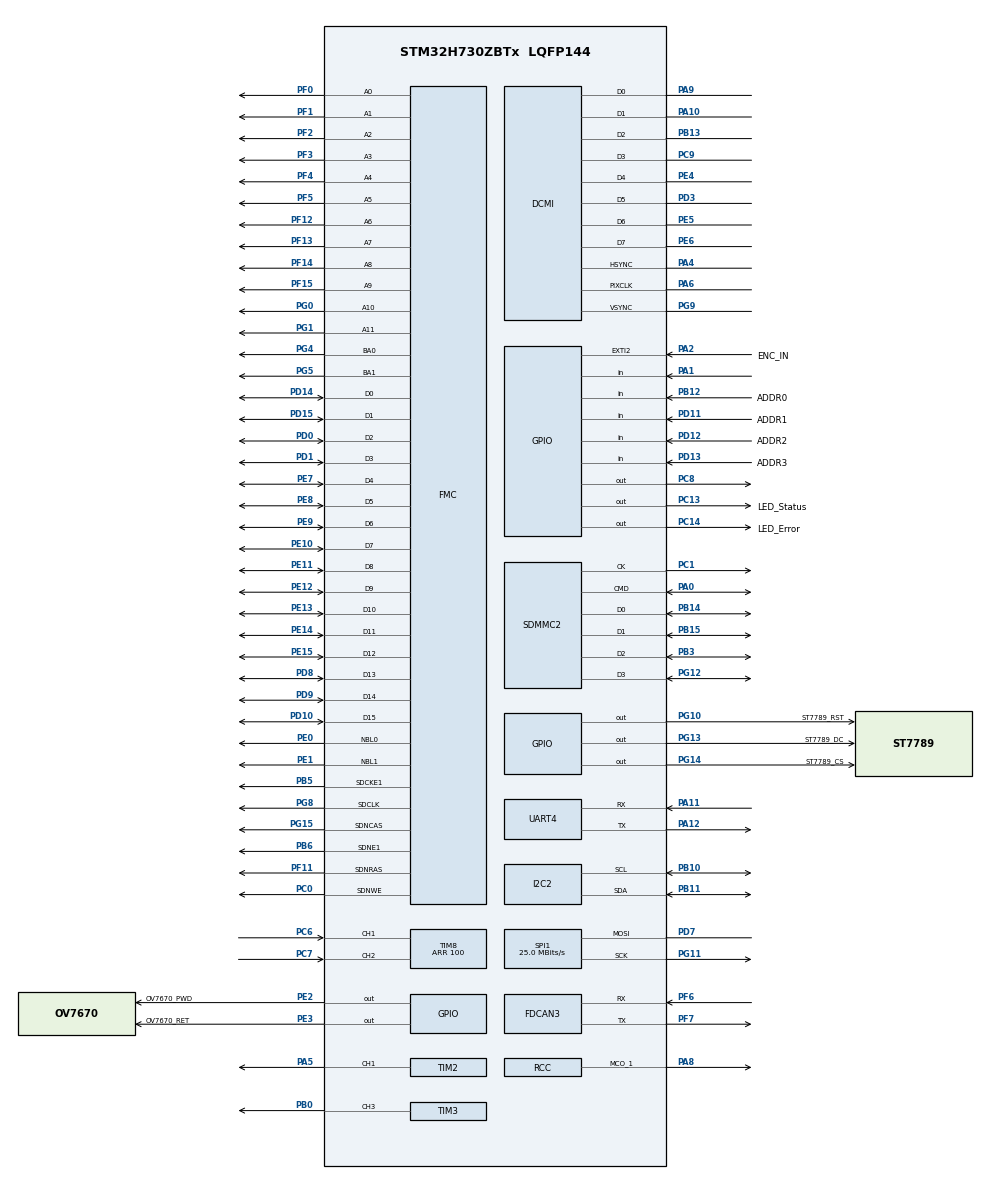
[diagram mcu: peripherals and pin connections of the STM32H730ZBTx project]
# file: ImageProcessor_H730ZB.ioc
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CORTEX_M7.CPU_DCache=Enabled
CORTEX_M7.CPU_ICache=Enabled
DCMI.JPEGMode=DCMI_JPEG_DISABLE
DCMI.PCKPolarity=DCMI_PCKPOLARITY_RISING
DCMI.VSPolarity=DCMI_VSPOLARITY_HIGH
Dma.DCMI_PSSI.0.Direction=DMA_PERIPH_TO_MEMORY
Dma.DCMI_PSSI.0.EventEnable=DISABLE
Dma.DCMI_PSSI.0.FIFOMode=DMA_FIFOMODE_ENABLE
Dma.DCMI_PSSI.0.FIFOThreshold=DMA_FIFO_THRESHOLD_FULL
Dma.DCMI_PSSI.0.Instance=DMA2_Stream0
Dma.DCMI_PSSI.0.MemBurst=DMA_MBURST_SINGLE
Dma.DCMI_PSSI.0.MemDataAlignment=DMA_MDATAALIGN_WORD
Dma.DCMI_PSSI.0.MemInc=DMA_MINC_ENABLE
Dma.DCMI_PSSI.0.Mode=DMA_NORMAL
Dma.DCMI_PSSI.0.PeriphBurst=DMA_PBURST_SINGLE
Dma.DCMI_PSSI.0.PeriphDataAlignment=DMA_PDATAALIGN_WORD
Dma.DCMI_PSSI.0.PeriphInc=DMA_PINC_DISABLE
Dma.DCMI_PSSI.0.Polarity=HAL_DMAMUX_REQ_GEN_RISING
Dma.DCMI_PSSI.0.Priority=DMA_PRIORITY_VERY_HIGH
Dma.DCMI_PSSI.0.RequestNumber=1
Dma.DCMI_PSSI.0.SignalID=NONE
Dma.DCMI_PSSI.0.SyncEnable=ENABLE
Dma.DCMI_PSSI.0.SyncPolarity=HAL_DMAMUX_SYNC_RISING
Dma.DCMI_PSSI.0.SyncRequestNumber=1
Dma.DCMI_PSSI.0.SyncSignalID=NONE
Dma.Request0=DCMI_PSSI
Dma.Request1=TIM3_CH3
Dma.TIM3_CH3.1.Direction=DMA_MEMORY_TO_PERIPH
Dma.TIM3_CH3.1.EventEnable=DISABLE
Dma.TIM3_CH3.1.FIFOMode=DMA_FIFOMODE_DISABLE
Dma.TIM3_CH3.1.Instance=DMA1_Stream0
Dma.TIM3_CH3.1.MemDataAlignment=DMA_MDATAALIGN_HALFWORD
Dma.TIM3_CH3.1.MemInc=DMA_MINC_ENABLE
Dma.TIM3_CH3.1.Mode=DMA_NORMAL
Dma.TIM3_CH3.1.PeriphDataAlignment=DMA_PDATAALIGN_HALFWORD
Dma.TIM3_CH3.1.PeriphInc=DMA_PINC_DISABLE
Dma.TIM3_CH3.1.Polarity=HAL_DMAMUX_REQ_GEN_RISING
Dma.TIM3_CH3.1.Priority=DMA_PRIORITY_LOW
Dma.TIM3_CH3.1.RequestNumber=1
Dma.TIM3_CH3.1.SignalID=NONE
Dma.TIM3_CH3.1.SyncEnable=ENABLE
Dma.TIM3_CH3.1.SyncPolarity=HAL_DMAMUX_SYNC_RISING
Dma.TIM3_CH3.1.SyncRequestNumber=1
Dma.TIM3_CH3.1.SyncSignalID=NONE
FATFS.BSP.number=1
FATFS0.BSP.STBoard=false
FATFS0.BSP.api=Unknown
FATFS0.BSP.i2caddr=0
FATFS0.BSP.instance=PA1
FATFS0.BSP.ip=GPIO
FATFS0.BSP.mode=Input
FATFS0.BSP.name=Detect_SDIO
FATFS0.BSP.solution=PA1
FDCAN3.AutoRetransmission=ENABLE
FDCAN3.DataPrescaler=1
FDCAN3.DataSyncJumpWidth=8
FDCAN3.DataTimeSeg1=16
FDCAN3.DataTimeSeg2=16
FDCAN3.ExtFiltersNbr=0
FDCAN3.NominalPrescaler=2
FDCAN3.NominalSyncJumpWidth=8
FDCAN3.NominalTimeSeg1=37
FDCAN3.NominalTimeSeg2=10
FDCAN3.ProtocolException=ENABLE
FDCAN3.RxBuffersNbr=0
FDCAN3.RxFifo0ElmtsNbr=8
FDCAN3.RxFifo1ElmtsNbr=0
FDCAN3.StdFiltersNbr=1
FDCAN3.TransmitPause=DISABLE
FDCAN3.TxBuffersNbr=0
FDCAN3.TxEventsNbr=0
FDCAN3.TxFifoQueueElmtsNbr=8
FMC.BankMapConfig=FMC_SWAPBMAP_DISABLE
FMC.CASLatency1=FMC_SDRAM_CAS_LATENCY_3
FMC.ExitSelfRefreshDelay1=15
FMC.LoadToActiveDelay1=3
FMC.RCDDelay1=4
FMC.RPDelay1=4
FMC.RPDelay2=4
FMC.ReadBurst1=FMC_SDRAM_RBURST_DISABLE
FMC.ReadPipeDelay1=FMC_SDRAM_RPIPE_DELAY_2
FMC.ReadPipeDelay2=FMC_SDRAM_RPIPE_DELAY_2
FMC.RowCycleDelay1=12
FMC.RowCycleDelay2=12
FMC.SDClockPeriod1=FMC_SDRAM_CLOCK_PERIOD_3
FMC.SDClockPeriod2=FMC_SDRAM_CLOCK_PERIOD_3
FMC.SelfRefreshTime1=9
FMC.WriteRecoveryTime1=6
I2C2.Timing=0x10C0ECFF
Mcu.Family=STM32H7
Mcu.Name=STM32H730ZBTx
Mcu.Package=LQFP144
NVIC.DCMI_PSSI_IRQn=true\:0\:0\:false\:false\:true\:true\:true
NVIC.DMA1_Stream0_IRQn=true\:0\:0\:false\:false\:true\:false\:true
NVIC.DMA2_Stream0_IRQn=true\:0\:0\:false\:false\:true\:false\:true
NVIC.DMAMUX1_OVR_IRQn=true\:0\:0\:false\:false\:true\:false\:true
NVIC.EXTI2_IRQn=true\:0\:0\:false\:false\:true\:true\:true
NVIC.FDCAN3_IT0_IRQn=true\:0\:0\:false\:false\:true\:true\:true
NVIC.FDCAN3_IT1_IRQn=true\:0\:0\:false\:false\:true\:true\:true
NVIC.PriorityGroup=NVIC_PRIORITYGROUP_4
NVIC.SPI1_IRQn=true\:0\:0\:false\:false\:true\:true\:true
NVIC.TIM3_IRQn=true\:0\:0\:false\:false\:true\:true\:true
NVIC.TIM8_CC_IRQn=true\:0\:0\:false\:false\:true\:true\:true
PA0.Mode=SD_4_bits_Wide_bus
PA0.Signal=SDMMC2_CMD
PA1.Signal=GPIO_Input
PA10.Mode=Slave_8_bits_External_Synchro
PA10.Signal=DCMI_D1
PA11.Mode=Asynchronous
PA11.Signal=UART4_RX
PA12.Mode=Asynchronous
PA12.Signal=UART4_TX
PA13(JTMS/SWDIO).Mode=Serial_Wire
PA13(JTMS/SWDIO).Signal=DEBUG_JTMS-SWDIO
PA14(JTCK/SWCLK).Mode=Serial_Wire
PA14(JTCK/SWCLK).Signal=DEBUG_JTCK-SWCLK
PA2.GPIO_Label=ENC_IN
PA2.GPIO_ModeDefaultEXTI=GPIO_MODE_IT_FALLING
PA2.Signal=GPXTI2
PA4.Mode=Slave_8_bits_External_Synchro
PA4.Signal=DCMI_HSYNC
PA5.Signal=S_TIM2_CH1
PA6.Mode=Slave_8_bits_External_Synchro
PA6.Signal=DCMI_PIXCLK
PA8.GPIO_Speed=GPIO_SPEED_FREQ_LOW
PA8.Mode=Clock-out-1
PA8.Signal=RCC_MCO_1
PA9.Mode=Slave_8_bits_External_Synchro
PA9.Signal=DCMI_D0
PB0.Signal=S_TIM3_CH3
PB10.Mode=I2C
PB10.Signal=I2C2_SCL
PB11.Mode=I2C
PB11.Signal=I2C2_SDA
PB12.GPIO_Label=ADDR0
PB12.Signal=GPIO_Input
PB13.Mode=Slave_8_bits_External_Synchro
PB13.Signal=DCMI_D2
PB14.Mode=SD_4_bits_Wide_bus
PB14.Signal=SDMMC2_D0
PB15.Mode=SD_4_bits_Wide_bus
PB15.Signal=SDMMC2_D1
PB3(JTDO/TRACESWO).Mode=SD_4_bits_Wide_bus
PB3(JTDO/TRACESWO).Signal=SDMMC2_D2
PB5.Mode=SdramChipSelect2_1
PB5.Signal=FMC_SDCKE1
PB6.Mode=SdramChipSelect2_1
PB6.Signal=FMC_SDNE1
PC0.Signal=FMC_SDNWE
PC1.Mode=SD_4_bits_Wide_bus
PC1.Signal=SDMMC2_CK
PC13.GPIO_Label=LED_Status
PC13.Signal=GPIO_Output
PC14-OSC32_IN.GPIO_Label=LED_Error
PC14-OSC32_IN.Signal=GPIO_Output
PC6.Signal=S_TIM8_CH1
PC7.Signal=S_TIM8_CH2
PC8.Signal=GPIO_Output
PC9.Mode=Slave_8_bits_External_Synchro
PC9.Signal=DCMI_D3
PD0.Signal=FMC_D2_DA2
PD1.Signal=FMC_D3_DA3
PD10.Signal=FMC_D15_DA15
PD11.GPIO_Label=ADDR1
PD11.Signal=GPIO_Input
PD12.GPIO_Label=ADDR2
PD12.Signal=GPIO_Input
PD13.GPIO_Label=ADDR3
PD13.Signal=GPIO_Input
PD14.Signal=FMC_D0_DA0
PD15.Signal=FMC_D1_DA1
PD3.Mode=Slave_8_bits_External_Synchro
PD3.Signal=DCMI_D5
PD7.Mode=Simplex_Bidirectional_Master
PD7.Signal=SPI1_MOSI
PD8.Signal=FMC_D13_DA13
PD9.Signal=FMC_D14_DA14
PE0.Signal=FMC_NBL0
PE1.Signal=FMC_NBL1
PE10.Signal=FMC_D7_DA7
PE11.Signal=FMC_D8_DA8
PE12.Signal=FMC_D9_DA9
PE13.Signal=FMC_D10_DA10
PE14.Signal=FMC_D11_DA11
PE15.Signal=FMC_D12_DA12
PE2.GPIO_Label=OV7670_PWD
PE2.Signal=GPIO_Output
PE3.GPIO_Label=OV7670_RET
PE3.Signal=GPIO_Output
PE4.Mode=Slave_8_bits_External_Synchro
PE4.Signal=DCMI_D4
PE5.Mode=Slave_8_bits_External_Synchro
PE5.Signal=DCMI_D6
PE6.Mode=Slave_8_bits_External_Synchro
PE6.Signal=DCMI_D7
PE7.Signal=FMC_D4_DA4
PE8.Signal=FMC_D5_DA5
PE9.Signal=FMC_D6_DA6
PF0.Signal=FMC_A0
PF1.Signal=FMC_A1
PF11.Signal=FMC_SDNRAS
PF12.Signal=FMC_A6
PF13.Signal=FMC_A7
PF14.Signal=FMC_A8
PF15.Signal=FMC_A9
PF2.Signal=FMC_A2
PF3.Signal=FMC_A3
PF4.Signal=FMC_A4
PF5.Signal=FMC_A5
PF6.Mode=FDCAN_Activate
PF6.Signal=FDCAN3_RX
PF7.Mode=FDCAN_Activate
PF7.Signal=FDCAN3_TX
PG0.Signal=FMC_A10
PG1.Signal=FMC_A11
PG10.GPIO_Label=ST7789_RST
PG10.Signal=GPIO_Output
PG11.Mode=Simplex_Bidirectional_Master
PG11.Signal=SPI1_SCK
PG12.Mode=SD_4_bits_Wide_bus
PG12.Signal=SDMMC2_D3
PG13.GPIO_Label=ST7789_DC
PG13.Signal=GPIO_Output
PG14.GPIO_Label=ST7789_CS
PG14.Signal=GPIO_Output
PG15.Signal=FMC_SDNCAS
PG4.Signal=FMC_A14_BA0
PG5.Signal=FMC_A15_BA1
PG8.Signal=FMC_SDCLK
PG9.Mode=Slave_8_bits_External_Synchro
PG9.Signal=DCMI_VSYNC
PH0-OSC_IN.Mode=HSE-External-Oscillator
PH0-OSC_IN.Signal=RCC_OSC_IN
PH1-OSC_OUT.Mode=HSE-External-Oscillator
PH1-OSC_OUT.Signal=RCC_OSC_OUT
ProjectManager.HeapSize=0x200
ProjectManager.StackSize=0x400
ProjectManager.TargetToolchain=STM32CubeIDE
RCC.ADCFreq_Value=96750000
RCC.APB1Freq_Value=100000000
RCC.APB2Freq_Value=100000000
RCC.APB3Freq_Value=100000000
RCC.APB4Freq_Value=100000000
RCC.CortexFreq_Value=400000000
RCC.D1PPRE=RCC_APB3_DIV2
RCC.D2PPRE1=RCC_APB1_DIV2
RCC.D2PPRE2=RCC_APB2_DIV2
RCC.D3PPRE=RCC_APB4_DIV2
RCC.DIVM1=3
RCC.DIVN1=25
RCC.DIVP1=1
RCC.FDCANCLockSelection=RCC_FDCANCLKSOURCE_HSE
RCC.HCLKFreq_Value=200000000
RCC.HPRE=RCC_HCLK_DIV2
RCC.HSE_VALUE=48000000
RCC.PLL2_VCI_Range-AdvancedSettings=RCC_PLL2VCIRANGE_0
RCC.PLL2_VCO_SEL-AdvancedSettings=RCC_PLL2VCOMEDIUM
RCC.PLL3_VCO_SEL-AdvancedSettings=RCC_PLL3VCOWIDE
RCC.PLLFRACN=0
RCC.PLLSourceVirtual=RCC_PLLSOURCE_HSE
RCC.RCC_MCODiv1=RCC_MCODIV_8
RCC.SYSCLKFreq_VALUE=400000000
RCC.SYSCLKSource=RCC_SYSCLKSOURCE_PLLCLK
RCC.USBFreq_Value=200000000
SH.FMC_A0.0=FMC_A0,12b-sda1
SH.FMC_A1.0=FMC_A1,12b-sda1
SH.FMC_A10.0=FMC_A10,12b-sda1
SH.FMC_A11.0=FMC_A11,12b-sda1
SH.FMC_A14_BA0.0=FMC_BA0,FourSdramBanks1
SH.FMC_A15_BA1.0=FMC_BA1,FourSdramBanks1
SH.FMC_A2.0=FMC_A2,12b-sda1
SH.FMC_A3.0=FMC_A3,12b-sda1
SH.FMC_A4.0=FMC_A4,12b-sda1
SH.FMC_A5.0=FMC_A5,12b-sda1
SH.FMC_A6.0=FMC_A6,12b-sda1
SH.FMC_A7.0=FMC_A7,12b-sda1
SH.FMC_A8.0=FMC_A8,12b-sda1
SH.FMC_A9.0=FMC_A9,12b-sda1
SH.FMC_D0_DA0.0=FMC_D0,sd-16b-d1
SH.FMC_D10_DA10.0=FMC_D10,sd-16b-d1
SH.FMC_D11_DA11.0=FMC_D11,sd-16b-d1
SH.FMC_D12_DA12.0=FMC_D12,sd-16b-d1
SH.FMC_D13_DA13.0=FMC_D13,sd-16b-d1
SH.FMC_D14_DA14.0=FMC_D14,sd-16b-d1
SH.FMC_D15_DA15.0=FMC_D15,sd-16b-d1
SH.FMC_D1_DA1.0=FMC_D1,sd-16b-d1
SH.FMC_D2_DA2.0=FMC_D2,sd-16b-d1
SH.FMC_D3_DA3.0=FMC_D3,sd-16b-d1
SH.FMC_D4_DA4.0=FMC_D4,sd-16b-d1
SH.FMC_D5_DA5.0=FMC_D5,sd-16b-d1
SH.FMC_D6_DA6.0=FMC_D6,sd-16b-d1
SH.FMC_D7_DA7.0=FMC_D7,sd-16b-d1
SH.FMC_D8_DA8.0=FMC_D8,sd-16b-d1
SH.FMC_D9_DA9.0=FMC_D9,sd-16b-d1
SH.FMC_NBL0.0=FMC_NBL0,Sd2ByteEnable1
SH.FMC_NBL1.0=FMC_NBL1,Sd2ByteEnable1
SH.FMC_SDCLK.0=FMC_SDCLK,12b-sda1
SH.FMC_SDNCAS.0=FMC_SDNCAS,12b-sda1
SH.FMC_SDNRAS.0=FMC_SDNRAS,12b-sda1
SH.FMC_SDNWE.0=FMC_SDNWE,12b-sda1
SH.S_TIM2_CH1.0=TIM2_CH1,PWM Generation1 CH1
SH.S_TIM3_CH3.0=TIM3_CH3,PWM Generation3 CH3
SH.S_TIM8_CH1.0=TIM8_CH1,Encoder_Interface
SH.S_TIM8_CH2.0=TIM8_CH2,Encoder_Interface
SPI1.BaudRatePrescaler=SPI_BAUDRATEPRESCALER_8
SPI1.CLKPolarity=SPI_POLARITY_HIGH
SPI1.CalculateBaudRate=25.0 MBits/s
SPI1.DataSize=SPI_DATASIZE_8BIT
SPI1.Direction=SPI_DIRECTION_1LINE
SPI1.Mode=SPI_MODE_MASTER
SPI1.NSSPMode=SPI_NSS_PULSE_DISABLE
SPI1.VirtualType=VM_MASTER
TIM2.Channel-PWM\ Generation1\ CH1=TIM_CHANNEL_1
TIM2.Period=100
TIM2.Prescaler=2000
TIM2.Pulse-PWM\ Generation1\ CH1=50
TIM3.AutoReloadPreload=TIM_AUTORELOAD_PRELOAD_DISABLE
TIM3.Channel-PWM\ Generation3\ CH3=TIM_CHANNEL_3
TIM3.Period=228
TIM3.Prescaler=0
TIM3.Pulse-PWM\ Generation3\ CH3=0
TIM8.AutoReloadPreload=TIM_AUTORELOAD_PRELOAD_ENABLE
TIM8.EncoderMode=TIM_ENCODERMODE_TI12
TIM8.IC1Filter=10
TIM8.IC1Polarity=TIM_ICPOLARITY_FALLING
TIM8.IC2Filter=10
TIM8.Period=100
VP_FATFS_VS_SDIO.Mode=SDIO
VP_TIM2_VS_ClockSourceINT.Mode=Internal
VP_TIM3_VS_ClockSourceINT.Mode=Internal
board=custom

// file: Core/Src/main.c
/* USER CODE BEGIN Header */
/**
  ******************************************************************************
  * @file           : main.c
  * @brief          : Main program body
  ******************************************************************************
  * @attention
  *
  * <h2><center>&copy; Copyright (c) 2020 STMicroelectronics.
  * All rights reserved.</center></h2>
  *
  * This software component is licensed by ST under BSD 3-Clause license,
  * the "License"; You may not use this file except in compliance with the
  * License. You may obtain a copy of the License at:
  *                        opensource.org/licenses/BSD-3-Clause
  *
  ******************************************************************************
  */
/* USER CODE END Header */
#include "main.h"
#include "fatfs.h"

/* USER CODE BEGIN Includes */

#include "ws2812.h"
#include "ov7670.h"
#include "st7789.h"
#include "menu.h"
#include "globals.h"

/* USER CODE END Includes */

/* USER CODE BEGIN PD */

#define BEST_LIGHTNING 55
/* USER CODE END PD */

DCMI_HandleTypeDef hdcmi;
DMA_HandleTypeDef hdma_dcmi_pssi;

FDCAN_HandleTypeDef hfdcan3;

I2C_HandleTypeDef hi2c2;

SD_HandleTypeDef hsd2;

SPI_HandleTypeDef hspi1;

TIM_HandleTypeDef htim2;
TIM_HandleTypeDef htim3;
TIM_HandleTypeDef htim8;
DMA_HandleTypeDef hdma_tim3_ch3;

UART_HandleTypeDef huart4;

SDRAM_HandleTypeDef hsdram1;

/* USER CODE BEGIN PV */
FMC_SDRAM_CommandTypeDef command;

uint16_t framebuffer[OV7670_QVGA_HEIGHT][OV7670_QVGA_WIDTH ];
//WRITE_READ_ADDR
uint16_t *sdramptr = (__IO uint16_t*) (SDRAM_BANK_ADDR );

unsigned char img[MAXYDIM][MAXXDIM];

uint8_t btn_enc = 0;
uint8_t pic_captured = 0;
uint8_t pic_written = 1;
uint8_t led_val;
uint8_t led_val_changed = 0;

//uint32_t cursorLine = 0;
//uint8_t cursorChanged = 0;

/* USER CODE END PV */

void SystemClock_Config(void);
static void MX_GPIO_Init(void);
static void MX_DMA_Init(void);
static void MX_FMC_Init(void);
static void MX_DCMI_Init(void);
static void MX_I2C2_Init(void);
static void MX_SPI1_Init(void);
static void MX_TIM8_Init(void);
static void MX_SDMMC2_SD_Init(void);
static void MX_TIM2_Init(void);
static void MX_UART4_Init(void);
static void MX_TIM3_Init(void);
static void MX_FDCAN3_Init(void);
/* USER CODE BEGIN PFP */
static void SDRAM_Initialization_Sequence(SDRAM_HandleTypeDef *hsdram, FMC_SDRAM_CommandTypeDef *Command);

/* USER CODE END PFP */

/* USER CODE BEGIN 0 */

// Buffers for CAN transmit and can receive
__IO uint8_t ubKeyNumber = 0x0;
FDCAN_RxHeaderTypeDef RxHeader;
uint8_t RxData[8];
FDCAN_TxHeaderTypeDef TxHeader;
uint8_t TxData[8];

/* Read/Write Buffers for RAM test*/
uint32_t aTxBuffer[BUFFER_SIZE];
uint32_t aRxBuffer[BUFFER_SIZE];

/* Status variables */
__IO uint32_t uwWriteReadStatus = 0;
/* Counter index */
uint32_t uwIndex = 0;

static void Fill_Buffer(uint32_t *pBuffer, uint32_t uwBufferLenght, uint32_t uwOffset)
{
  uint32_t tmpIndex = 0;

  /* Put in global buffer different values */
  for (tmpIndex = 0; tmpIndex < uwBufferLenght; tmpIndex++ )
  {
    pBuffer[tmpIndex] = tmpIndex + uwOffset;
  }
}

void SD_RAM_TEST() {
	  /*##-2- SDRAM memory read/write access #####################################*/

	  /* Write data to the SDRAM memory */
	  for(int i = 0; i < 50; i++){
		  /* Fill the buffer to write */
		  Fill_Buffer(aTxBuffer, BUFFER_SIZE, 0xA244250F);

		    /* Fill the Read buffer */
		  Fill_Buffer(aRxBuffer, BUFFER_SIZE, 0xBBBBBBBB);
		  for (uwIndex = 0; uwIndex < BUFFER_SIZE; uwIndex++)
		  {
			*(__IO uint32_t*) (SDRAM_BANK_ADDR + (WRITE_READ_ADDR*i) + 4*uwIndex) = aTxBuffer[uwIndex];
		  }

		  /* Read back data from the SDRAM memory */
		  for (uwIndex = 0; uwIndex < BUFFER_SIZE; uwIndex++)
		  {
			aRxBuffer[uwIndex] = *(__IO uint32_t*) (SDRAM_BANK_ADDR + (WRITE_READ_ADDR*i) + 4*uwIndex);
		  }

		  /*##-3- Checking data integrity ############################################*/

		  for (uwIndex = 0; (uwIndex < BUFFER_SIZE) && (uwWriteReadStatus == 0); uwIndex++)
		  {
			if (aRxBuffer[uwIndex] != aTxBuffer[uwIndex])
			{
			  uwWriteReadStatus++;
			}
		  }
	  }

	  if (uwWriteReadStatus != 0)//PASSED)
	  {
	    /* KO */
	    /* Toggle LED3 */
	    while(1)
	    {
	    	HAL_GPIO_TogglePin(LED_Status_GPIO_Port, LED_Status_Pin);
	    	HAL_Delay(500);
	      //BSP_LED_Toggle(LED3);
	    }
	  }
	  else
	  {
	    /* OK, turn on LED1 */
		  HAL_GPIO_TogglePin(LED_Status_GPIO_Port, LED_Status_Pin);
	    //BSP_LED_On(LED1);
	  }
}

/* USER CODE END 0 */

int main(void)
{

  /* Enable I-Cache---------------------------------------------------------*/
  SCB_EnableICache();

  /* Enable D-Cache---------------------------------------------------------*/
  SCB_EnableDCache();

  /* MCU Configuration--------------------------------------------------------*/

  /* Reset of all peripherals, Initializes the Flash interface and the Systick. */
  HAL_Init();

  /* Configure the system clock */
  SystemClock_Config();

  /* Initialize all configured peripherals */
  MX_GPIO_Init();
  MX_DMA_Init();
  MX_FMC_Init();
  MX_DCMI_Init();
  MX_I2C2_Init();
  MX_SPI1_Init();
  MX_TIM8_Init();
  MX_SDMMC2_SD_Init();
  MX_TIM2_Init();
  MX_UART4_Init();
  MX_TIM3_Init();
  MX_FATFS_Init();
  MX_FDCAN3_Init();
  /* USER CODE BEGIN 2 */

  for(unsigned int x = 0; x < OV7670_QVGA_WIDTH; x++){
	  for(unsigned int y = 0; y < OV7670_QVGA_HEIGHT; y++){
	  framebuffer[y][x] = 0;
	  }
  }

  ov7670_init(&hdcmi, &hdma_dcmi_pssi, &hi2c2);
  ov7670_config(1);

  led_init();
  // init spi display
  ST7789_Init();
  // Set PWM Backlight to 50%
  HAL_TIM_PWM_Start(&htim2, TIM_CHANNEL_2);

  // Start encoder
  HAL_TIM_Encoder_Start_IT(&htim8, TIM_CHANNEL_ALL);
  /* USER CODE END 2 */

  /* Infinite loop */
  /* USER CODE BEGIN WHILE */
  SD_RAM_TEST();
  int blaa = 0;
  uint8_t led_val = 55;
  led_fill(led_val,led_val,led_val);
  led_show();

  //HAL_FDCAN_Start(&hfdcan3);
  //HAL_TIM_PWM_Start_DMA(&htim3, TIM_CHANNEL_3,(uint32_t*) &BUF_DMA, (uint16_t)ARRAY_LEN);
  while (1)
  {
	  //menu();
	 /*
	  if(btn_enc){
		  toggle_led ^= 1;
		  if(toggle_led){
			  led_fill(led_val,led_val,led_val);
			  led_show();
		  }else{
			  led_fill(0,0,0);
			  led_show();
		  }
		  HAL_Delay(100);
		  btn_enc = 0;
		  HAL_NVIC_EnableIRQ(EXTI9_5_IRQn);
	  }
	  */
	  if(pic_captured == 0 /*&& pic_written == 1*/){
		  //ov7670_startCap(OV7670_CAP_SINGLE_FRAME, &framebuffer);
		  ov7670_startCap(OV7670_CAP_SINGLE_FRAME, sdramptr);
		  pic_written = 0;
		  pic_captured = 2;
	  }
	  if(pic_captured == 1){
		  blaa ++;
		  //memcpy(framebuffer, sdramptr, sizeof(framebuffer));
/*		  led_val = (uint8_t)(blaa % 50);
		  led_fill(led_val,led_val,led_val);
		  led_show();*/
		  pic_captured = 0;
		  ov7670_stopCap();
		  ST7789_DrawImage(0,0,320,240,sdramptr);
		  //ST7789_DrawImage(0,0,320,240,framebuffer);
	  }
	  /*HAL_Delay(500);
      TxData[0] = 0xFF;
      TxData[1] = 0xAB;
      TxData[2] = 0xAC;
      TxData[3] = 0xAD;
      TxData[4] = 0xAE;

      if (HAL_FDCAN_AddMessageToTxFifoQ(&hfdcan3, &TxHeader, TxData) != HAL_OK)
      {
        //Error_Handler();
      }
      */

	  //HAL_FDCAN_AddMessageToTxBuffer(&hfdcan3, , pTxData, BufferIndex)

	  //ST7789_Test();
    /* USER CODE END WHILE */

  }
}

void SystemClock_Config(void)
{
  RCC_OscInitTypeDef RCC_OscInitStruct = {0};
  RCC_ClkInitTypeDef RCC_ClkInitStruct = {0};
  RCC_PeriphCLKInitTypeDef PeriphClkInitStruct = {0};

  /** Supply configuration update enable
  */
  HAL_PWREx_ConfigSupply(PWR_LDO_SUPPLY);
  /** Configure the main internal regulator output voltage
  */
  __HAL_PWR_VOLTAGESCALING_CONFIG(PWR_REGULATOR_VOLTAGE_SCALE1);

  while(!__HAL_PWR_GET_FLAG(PWR_FLAG_VOSRDY)) {}
  /** Initializes the RCC Oscillators according to the specified parameters
  * in the RCC_OscInitTypeDef structure.
  */
  RCC_OscInitStruct.OscillatorType = RCC_OSCILLATORTYPE_HSI|RCC_OSCILLATORTYPE_HSE;
  RCC_OscInitStruct.HSEState = RCC_HSE_ON;
  RCC_OscInitStruct.HSIState = RCC_HSI_DIV1;
  RCC_OscInitStruct.HSICalibrationValue = RCC_HSICALIBRATION_DEFAULT;
  RCC_OscInitStruct.PLL.PLLState = RCC_PLL_ON;
  RCC_OscInitStruct.PLL.PLLSource = RCC_PLLSOURCE_HSE;
  RCC_OscInitStruct.PLL.PLLM = 3;
  RCC_OscInitStruct.PLL.PLLN = 25;
  RCC_OscInitStruct.PLL.PLLP = 1;
  RCC_OscInitStruct.PLL.PLLQ = 2;
  RCC_OscInitStruct.PLL.PLLR = 2;
  RCC_OscInitStruct.PLL.PLLRGE = RCC_PLL1VCIRANGE_3;
  RCC_OscInitStruct.PLL.PLLVCOSEL = RCC_PLL1VCOWIDE;
  RCC_OscInitStruct.PLL.PLLFRACN = 0;
  if (HAL_RCC_OscConfig(&RCC_OscInitStruct) != HAL_OK)
  {
    Error_Handler();
  }
  /** Initializes the CPU, AHB and APB buses clocks
  */
  RCC_ClkInitStruct.ClockType = RCC_CLOCKTYPE_HCLK|RCC_CLOCKTYPE_SYSCLK
                              |RCC_CLOCKTYPE_PCLK1|RCC_CLOCKTYPE_PCLK2
                              |RCC_CLOCKTYPE_D3PCLK1|RCC_CLOCKTYPE_D1PCLK1;
  RCC_ClkInitStruct.SYSCLKSource = RCC_SYSCLKSOURCE_PLLCLK;
  RCC_ClkInitStruct.SYSCLKDivider = RCC_SYSCLK_DIV1;
  RCC_ClkInitStruct.AHBCLKDivider = RCC_HCLK_DIV2;
  RCC_ClkInitStruct.APB3CLKDivider = RCC_APB3_DIV2;
  RCC_ClkInitStruct.APB1CLKDivider = RCC_APB1_DIV2;
  RCC_ClkInitStruct.APB2CLKDivider = RCC_APB2_DIV2;
  RCC_ClkInitStruct.APB4CLKDivider = RCC_APB4_DIV2;

  if (HAL_RCC_ClockConfig(&RCC_ClkInitStruct, FLASH_LATENCY_2) != HAL_OK)
  {
    Error_Handler();
  }
  PeriphClkInitStruct.PeriphClockSelection = RCC_PERIPHCLK_UART4|RCC_PERIPHCLK_FDCAN
                              |RCC_PERIPHCLK_SPI1|RCC_PERIPHCLK_SDMMC
                              |RCC_PERIPHCLK_I2C2|RCC_PERIPHCLK_FMC;
  PeriphClkInitStruct.FmcClockSelection = RCC_FMCCLKSOURCE_D1HCLK;
  PeriphClkInitStruct.SdmmcClockSelection = RCC_SDMMCCLKSOURCE_PLL;
  PeriphClkInitStruct.Spi123ClockSelection = RCC_SPI123CLKSOURCE_PLL;
  PeriphClkInitStruct.FdcanClockSelection = RCC_FDCANCLKSOURCE_HSE;
  PeriphClkInitStruct.Usart234578ClockSelection = RCC_USART234578CLKSOURCE_D2PCLK1;
  PeriphClkInitStruct.I2c1235ClockSelection = RCC_I2C1235CLKSOURCE_D2PCLK1;
  if (HAL_RCCEx_PeriphCLKConfig(&PeriphClkInitStruct) != HAL_OK)
  {
    Error_Handler();
  }
  HAL_RCC_MCOConfig(RCC_MCO1, RCC_MCO1SOURCE_HSI, RCC_MCODIV_8);
}

static void MX_DCMI_Init(void)
{

  hdcmi.Instance = DCMI;
  hdcmi.Init.SynchroMode = DCMI_SYNCHRO_HARDWARE;
  hdcmi.Init.PCKPolarity = DCMI_PCKPOLARITY_RISING;
  hdcmi.Init.VSPolarity = DCMI_VSPOLARITY_HIGH;
  hdcmi.Init.HSPolarity = DCMI_HSPOLARITY_LOW;
  hdcmi.Init.CaptureRate = DCMI_CR_ALL_FRAME;
  hdcmi.Init.ExtendedDataMode = DCMI_EXTEND_DATA_8B;
  hdcmi.Init.JPEGMode = DCMI_JPEG_DISABLE;
  hdcmi.Init.ByteSelectMode = DCMI_BSM_ALL;
  hdcmi.Init.ByteSelectStart = DCMI_OEBS_ODD;
  hdcmi.Init.LineSelectMode = DCMI_LSM_ALL;
  hdcmi.Init.LineSelectStart = DCMI_OELS_ODD;
  if (HAL_DCMI_Init(&hdcmi) != HAL_OK)
  {
    Error_Handler();
  }

}

static void MX_FDCAN3_Init(void)
{

  /* USER CODE BEGIN FDCAN3_Init 0 */

	// --------- configure CAN to 500kb/s -----------------
	FDCAN_FilterTypeDef sFilterConfig;

  /* USER CODE END FDCAN3_Init 0 */

  hfdcan3.Instance = FDCAN3;
  hfdcan3.Init.FrameFormat = FDCAN_FRAME_CLASSIC;
  hfdcan3.Init.Mode = FDCAN_MODE_NORMAL;
  hfdcan3.Init.AutoRetransmission = ENABLE;
  hfdcan3.Init.TransmitPause = DISABLE;
  hfdcan3.Init.ProtocolException = ENABLE;
  hfdcan3.Init.NominalPrescaler = 2;
  hfdcan3.Init.NominalSyncJumpWidth = 8;
  hfdcan3.Init.NominalTimeSeg1 = 37;
  hfdcan3.Init.NominalTimeSeg2 = 10;
  hfdcan3.Init.DataPrescaler = 1;
  hfdcan3.Init.DataSyncJumpWidth = 8;
  hfdcan3.Init.DataTimeSeg1 = 16;
  hfdcan3.Init.DataTimeSeg2 = 16;
  hfdcan3.Init.MessageRAMOffset = 0;
  hfdcan3.Init.StdFiltersNbr = 1;
  hfdcan3.Init.ExtFiltersNbr = 0;
  hfdcan3.Init.RxFifo0ElmtsNbr = 8;
  hfdcan3.Init.RxFifo0ElmtSize = FDCAN_DATA_BYTES_8;
  hfdcan3.Init.RxFifo1ElmtsNbr = 0;
  hfdcan3.Init.RxFifo1ElmtSize = FDCAN_DATA_BYTES_8;
  hfdcan3.Init.RxBuffersNbr = 0;
  hfdcan3.Init.RxBufferSize = FDCAN_DATA_BYTES_8;
  hfdcan3.Init.TxEventsNbr = 0;
  hfdcan3.Init.TxBuffersNbr = 0;
  hfdcan3.Init.TxFifoQueueElmtsNbr = 8;
  hfdcan3.Init.TxFifoQueueMode = FDCAN_TX_FIFO_OPERATION;
  hfdcan3.Init.TxElmtSize = FDCAN_DATA_BYTES_8;
  if (HAL_FDCAN_Init(&hfdcan3) != HAL_OK)
  {
    Error_Handler();
  }
  /* USER CODE BEGIN FDCAN3_Init 2 */

  /* Configure Rx filter */
  sFilterConfig.IdType = FDCAN_STANDARD_ID;
  sFilterConfig.FilterIndex = 0;
  sFilterConfig.FilterType = FDCAN_FILTER_MASK;
  sFilterConfig.FilterConfig = FDCAN_FILTER_TO_RXFIFO0;
  sFilterConfig.FilterID1 = 0x321;
  sFilterConfig.FilterID2 = 0x7FF;
  if (HAL_FDCAN_ConfigFilter(&hfdcan3, &sFilterConfig) != HAL_OK)
  {
    /* Filter configuration Error */
    Error_Handler();
  }

  /* Start the FDCAN module */
  if (HAL_FDCAN_Start(&hfdcan3) != HAL_OK)
  {
    /* Start Error */
    Error_Handler();
  }

  if (HAL_FDCAN_ActivateNotification(&hfdcan3, FDCAN_IT_RX_FIFO0_NEW_MESSAGE, 0) != HAL_OK)
  {
    /* Notification Error */
    Error_Handler();
  }

  /* Prepare Tx Header */
  TxHeader.Identifier = 0x321;
  TxHeader.IdType = FDCAN_STANDARD_ID;
  TxHeader.TxFrameType = FDCAN_DATA_FRAME;
  TxHeader.DataLength = FDCAN_DLC_BYTES_2;
  TxHeader.ErrorStateIndicator = FDCAN_ESI_ACTIVE;
  TxHeader.BitRateSwitch = FDCAN_BRS_OFF;
  TxHeader.FDFormat = FDCAN_CLASSIC_CAN;
  TxHeader.TxEventFifoControl = FDCAN_NO_TX_EVENTS;
  TxHeader.MessageMarker = 0;

  /* USER CODE END FDCAN3_Init 2 */

}

static void MX_I2C2_Init(void)
{

  hi2c2.Instance = I2C2;
  hi2c2.Init.Timing = 0x10C0ECFF;
  hi2c2.Init.OwnAddress1 = 0;
  hi2c2.Init.AddressingMode = I2C_ADDRESSINGMODE_7BIT;
  hi2c2.Init.DualAddressMode = I2C_DUALADDRESS_DISABLE;
  hi2c2.Init.OwnAddress2 = 0;
  hi2c2.Init.OwnAddress2Masks = I2C_OA2_NOMASK;
  hi2c2.Init.GeneralCallMode = I2C_GENERALCALL_DISABLE;
  hi2c2.Init.NoStretchMode = I2C_NOSTRETCH_DISABLE;
  if (HAL_I2C_Init(&hi2c2) != HAL_OK)
  {
    Error_Handler();
  }
  /** Configure Analogue filter
  */
  if (HAL_I2CEx_ConfigAnalogFilter(&hi2c2, I2C_ANALOGFILTER_ENABLE) != HAL_OK)
  {
    Error_Handler();
  }
  /** Configure Digital filter
  */
  if (HAL_I2CEx_ConfigDigitalFilter(&hi2c2, 0) != HAL_OK)
  {
    Error_Handler();
  }

}

static void MX_SDMMC2_SD_Init(void)
{

  hsd2.Instance = SDMMC2;
  hsd2.Init.ClockEdge = SDMMC_CLOCK_EDGE_RISING;
  hsd2.Init.ClockPowerSave = SDMMC_CLOCK_POWER_SAVE_DISABLE;
  hsd2.Init.BusWide = SDMMC_BUS_WIDE_4B;
  hsd2.Init.HardwareFlowControl = SDMMC_HARDWARE_FLOW_CONTROL_DISABLE;
  hsd2.Init.ClockDiv = 0;
  hsd2.Init.TranceiverPresent = SDMMC_TRANSCEIVER_NOT_PRESENT;

}

static void MX_SPI1_Init(void)
{

  /* SPI1 parameter configuration*/
  hspi1.Instance = SPI1;
  hspi1.Init.Mode = SPI_MODE_MASTER;
  hspi1.Init.Direction = SPI_DIRECTION_1LINE;
  hspi1.Init.DataSize = SPI_DATASIZE_8BIT;
  hspi1.Init.CLKPolarity = SPI_POLARITY_HIGH;
  hspi1.Init.CLKPhase = SPI_PHASE_1EDGE;
  hspi1.Init.NSS = SPI_NSS_SOFT;
  hspi1.Init.BaudRatePrescaler = SPI_BAUDRATEPRESCALER_8;
  hspi1.Init.FirstBit = SPI_FIRSTBIT_MSB;
  hspi1.Init.TIMode = SPI_TIMODE_DISABLE;
  hspi1.Init.CRCCalculation = SPI_CRCCALCULATION_DISABLE;
  hspi1.Init.CRCPolynomial = 0x0;
  hspi1.Init.NSSPMode = SPI_NSS_PULSE_DISABLE;
  hspi1.Init.NSSPolarity = SPI_NSS_POLARITY_LOW;
  hspi1.Init.FifoThreshold = SPI_FIFO_THRESHOLD_01DATA;
  hspi1.Init.TxCRCInitializationPattern = SPI_CRC_INITIALIZATION_ALL_ZERO_PATTERN;
  hspi1.Init.RxCRCInitializationPattern = SPI_CRC_INITIALIZATION_ALL_ZERO_PATTERN;
  hspi1.Init.MasterSSIdleness = SPI_MASTER_SS_IDLENESS_00CYCLE;
  hspi1.Init.MasterInterDataIdleness = SPI_MASTER_INTERDATA_IDLENESS_00CYCLE;
  hspi1.Init.MasterReceiverAutoSusp = SPI_MASTER_RX_AUTOSUSP_DISABLE;
  hspi1.Init.MasterKeepIOState = SPI_MASTER_KEEP_IO_STATE_DISABLE;
  hspi1.Init.IOSwap = SPI_IO_SWAP_DISABLE;
  if (HAL_SPI_Init(&hspi1) != HAL_OK)
  {
    Error_Handler();
  }

}

static void MX_TIM2_Init(void)
{

  TIM_ClockConfigTypeDef sClockSourceConfig = {0};
  TIM_MasterConfigTypeDef sMasterConfig = {0};
  TIM_OC_InitTypeDef sConfigOC = {0};

  htim2.Instance = TIM2;
  htim2.Init.Prescaler = 2000;
  htim2.Init.CounterMode = TIM_COUNTERMODE_UP;
  htim2.Init.Period = 100;
  htim2.Init.ClockDivision = TIM_CLOCKDIVISION_DIV1;
  htim2.Init.AutoReloadPreload = TIM_AUTORELOAD_PRELOAD_DISABLE;
  if (HAL_TIM_Base_Init(&htim2) != HAL_OK)
  {
    Error_Handler();
  }
  sClockSourceConfig.ClockSource = TIM_CLOCKSOURCE_INTERNAL;
  if (HAL_TIM_ConfigClockSource(&htim2, &sClockSourceConfig) != HAL_OK)
  {
    Error_Handler();
  }
  if (HAL_TIM_PWM_Init(&htim2) != HAL_OK)
  {
    Error_Handler();
  }
  sMasterConfig.MasterOutputTrigger = TIM_TRGO_RESET;
  sMasterConfig.MasterSlaveMode = TIM_MASTERSLAVEMODE_DISABLE;
  if (HAL_TIMEx_MasterConfigSynchronization(&htim2, &sMasterConfig) != HAL_OK)
  {
    Error_Handler();
  }
  sConfigOC.OCMode = TIM_OCMODE_PWM1;
  sConfigOC.Pulse = 50;
  sConfigOC.OCPolarity = TIM_OCPOLARITY_HIGH;
  sConfigOC.OCFastMode = TIM_OCFAST_DISABLE;
  if (HAL_TIM_PWM_ConfigChannel(&htim2, &sConfigOC, TIM_CHANNEL_1) != HAL_OK)
  {
    Error_Handler();
  }
  HAL_TIM_MspPostInit(&htim2);

}

static void MX_TIM3_Init(void)
{

  TIM_ClockConfigTypeDef sClockSourceConfig = {0};
  TIM_MasterConfigTypeDef sMasterConfig = {0};
  TIM_OC_InitTypeDef sConfigOC = {0};

  htim3.Instance = TIM3;
  htim3.Init.Prescaler = 0;
  htim3.Init.CounterMode = TIM_COUNTERMODE_UP;
  htim3.Init.Period = 228;
  htim3.Init.ClockDivision = TIM_CLOCKDIVISION_DIV1;
  htim3.Init.AutoReloadPreload = TIM_AUTORELOAD_PRELOAD_DISABLE;
  if (HAL_TIM_Base_Init(&htim3) != HAL_OK)
  {
    Error_Handler();
  }
  sClockSourceConfig.ClockSource = TIM_CLOCKSOURCE_INTERNAL;
  if (HAL_TIM_ConfigClockSource(&htim3, &sClockSourceConfig) != HAL_OK)
  {
    Error_Handler();
  }
  if (HAL_TIM_PWM_Init(&htim3) != HAL_OK)
  {
    Error_Handler();
  }
  sMasterConfig.MasterOutputTrigger = TIM_TRGO_RESET;
  sMasterConfig.MasterSlaveMode = TIM_MASTERSLAVEMODE_DISABLE;
  if (HAL_TIMEx_MasterConfigSynchronization(&htim3, &sMasterConfig) != HAL_OK)
  {
    Error_Handler();
  }
  sConfigOC.OCMode = TIM_OCMODE_PWM1;
  sConfigOC.Pulse = 0;
  sConfigOC.OCPolarity = TIM_OCPOLARITY_HIGH;
  sConfigOC.OCFastMode = TIM_OCFAST_DISABLE;
  if (HAL_TIM_PWM_ConfigChannel(&htim3, &sConfigOC, TIM_CHANNEL_3) != HAL_OK)
  {
    Error_Handler();
  }
  /* USER CODE BEGIN TIM3_Init 2 */
  htim3.Init.Period = PWM_ARR;
  HAL_TIM_Base_Init(&htim3);

  //DMAMUX1_Channel0->CCR |= 25U;

  /* USER CODE END TIM3_Init 2 */
  HAL_TIM_MspPostInit(&htim3);

}

static void MX_TIM8_Init(void)
{

  TIM_Encoder_InitTypeDef sConfig = {0};
  TIM_MasterConfigTypeDef sMasterConfig = {0};

  htim8.Instance = TIM8;
  htim8.Init.Prescaler = 0;
  htim8.Init.CounterMode = TIM_COUNTERMODE_UP;
  htim8.Init.Period = 100;
  htim8.Init.ClockDivision = TIM_CLOCKDIVISION_DIV1;
  htim8.Init.RepetitionCounter = 0;
  htim8.Init.AutoReloadPreload = TIM_AUTORELOAD_PRELOAD_ENABLE;
  sConfig.EncoderMode = TIM_ENCODERMODE_TI12;
  sConfig.IC1Polarity = TIM_ICPOLARITY_FALLING;
  sConfig.IC1Selection = TIM_ICSELECTION_DIRECTTI;
  sConfig.IC1Prescaler = TIM_ICPSC_DIV1;
  sConfig.IC1Filter = 10;
  sConfig.IC2Polarity = TIM_ICPOLARITY_RISING;
  sConfig.IC2Selection = TIM_ICSELECTION_DIRECTTI;
  sConfig.IC2Prescaler = TIM_ICPSC_DIV1;
  sConfig.IC2Filter = 10;
  if (HAL_TIM_Encoder_Init(&htim8, &sConfig) != HAL_OK)
  {
    Error_Handler();
  }
  sMasterConfig.MasterOutputTrigger = TIM_TRGO_RESET;
  sMasterConfig.MasterOutputTrigger2 = TIM_TRGO2_RESET;
  sMasterConfig.MasterSlaveMode = TIM_MASTERSLAVEMODE_DISABLE;
  if (HAL_TIMEx_MasterConfigSynchronization(&htim8, &sMasterConfig) != HAL_OK)
  {
    Error_Handler();
  }

}

static void MX_UART4_Init(void)
{

  huart4.Instance = UART4;
  huart4.Init.BaudRate = 115200;
  huart4.Init.WordLength = UART_WORDLENGTH_8B;
  huart4.Init.StopBits = UART_STOPBITS_1;
  huart4.Init.Parity = UART_PARITY_NONE;
  huart4.Init.Mode = UART_MODE_TX_RX;
  huart4.Init.HwFlowCtl = UART_HWCONTROL_NONE;
  huart4.Init.OverSampling = UART_OVERSAMPLING_16;
  huart4.Init.OneBitSampling = UART_ONE_BIT_SAMPLE_DISABLE;
  huart4.Init.ClockPrescaler = UART_PRESCALER_DIV1;
  huart4.AdvancedInit.AdvFeatureInit = UART_ADVFEATURE_NO_INIT;
  if (HAL_UART_Init(&huart4) != HAL_OK)
  {
    Error_Handler();
  }
  if (HAL_UARTEx_SetTxFifoThreshold(&huart4, UART_TXFIFO_THRESHOLD_1_8) != HAL_OK)
  {
    Error_Handler();
  }
  if (HAL_UARTEx_SetRxFifoThreshold(&huart4, UART_RXFIFO_THRESHOLD_1_8) != HAL_OK)
  {
    Error_Handler();
  }
  if (HAL_UARTEx_DisableFifoMode(&huart4) != HAL_OK)
  {
    Error_Handler();
  }

}

static void MX_DMA_Init(void)
{

  /* DMA controller clock enable */
  __HAL_RCC_DMA2_CLK_ENABLE();
  __HAL_RCC_DMA1_CLK_ENABLE();

  /* DMA interrupt init */
  /* DMA1_Stream0_IRQn interrupt configuration */
  HAL_NVIC_SetPriority(DMA1_Stream0_IRQn, 0, 0);
  HAL_NVIC_EnableIRQ(DMA1_Stream0_IRQn);
  /* DMA2_Stream0_IRQn interrupt configuration */
  HAL_NVIC_SetPriority(DMA2_Stream0_IRQn, 0, 0);
  HAL_NVIC_EnableIRQ(DMA2_Stream0_IRQn);
  /* DMAMUX1_OVR_IRQn interrupt configuration */
  HAL_NVIC_SetPriority(DMAMUX1_OVR_IRQn, 0, 0);
  HAL_NVIC_EnableIRQ(DMAMUX1_OVR_IRQn);

}

/* FMC initialization function */
static void MX_FMC_Init(void)
{

  FMC_SDRAM_TimingTypeDef SdramTiming = {0};

  /** Perform the SDRAM1 memory initialization sequence
  */
  hsdram1.Instance = FMC_SDRAM_DEVICE;
  /* hsdram1.Init */
  hsdram1.Init.SDBank = FMC_SDRAM_BANK2;
  hsdram1.Init.ColumnBitsNumber = FMC_SDRAM_COLUMN_BITS_NUM_8;
  hsdram1.Init.RowBitsNumber = FMC_SDRAM_ROW_BITS_NUM_12;
  hsdram1.Init.MemoryDataWidth = FMC_SDRAM_MEM_BUS_WIDTH_16;
  hsdram1.Init.InternalBankNumber = FMC_SDRAM_INTERN_BANKS_NUM_4;
  hsdram1.Init.CASLatency = FMC_SDRAM_CAS_LATENCY_3;
  hsdram1.Init.WriteProtection = FMC_SDRAM_WRITE_PROTECTION_DISABLE;
  hsdram1.Init.SDClockPeriod = FMC_SDRAM_CLOCK_PERIOD_3;
  hsdram1.Init.ReadBurst = FMC_SDRAM_RBURST_DISABLE;
  hsdram1.Init.ReadPipeDelay = FMC_SDRAM_RPIPE_DELAY_2;
  /* SdramTiming */
  SdramTiming.LoadToActiveDelay = 3;
  SdramTiming.ExitSelfRefreshDelay = 15;
  SdramTiming.SelfRefreshTime = 9;
  SdramTiming.RowCycleDelay = 12;
  SdramTiming.WriteRecoveryTime = 6;
  SdramTiming.RPDelay = 4;
  SdramTiming.RCDDelay = 4;

  if (HAL_SDRAM_Init(&hsdram1, &SdramTiming) != HAL_OK)
  {
    Error_Handler( );
  }

  /* USER CODE BEGIN FMC_Init 2 */

  // RAM Clock 200MHz = 5ns
  // TRAS:  min=40ns (8)*5ns max=100k ns
  // TXSR: "ExitSelfRefreshDelay" min=70ns 	is (14) * 5ns
  // TRC:  min=55ns = (11)*5ns
  // TWR:  2 Clock cycles
  // TRP: 15ns = (3)*5ns
  // TRCD: 15ns = (3)*5ns

  /*
   * Timing backup
  SdramTiming.LoadToActiveDelay = 2;
  SdramTiming.ExitSelfRefreshDelay = 14;
  SdramTiming.SelfRefreshTime = 8;
  SdramTiming.RowCycleDelay = 11;
  SdramTiming.WriteRecoveryTime = 5;
  SdramTiming.RPDelay = 3;
  SdramTiming.RCDDelay = 3;
   */

  SDRAM_Initialization_Sequence(&hsdram1, &command);
  /* USER CODE END FMC_Init 2 */
}

static void MX_GPIO_Init(void)
{
  GPIO_InitTypeDef GPIO_InitStruct = {0};

  /* GPIO Ports Clock Enable */
  __HAL_RCC_GPIOE_CLK_ENABLE();
  __HAL_RCC_GPIOC_CLK_ENABLE();
  __HAL_RCC_GPIOF_CLK_ENABLE();
  __HAL_RCC_GPIOH_CLK_ENABLE();
  __HAL_RCC_GPIOA_CLK_ENABLE();
  __HAL_RCC_GPIOB_CLK_ENABLE();
  __HAL_RCC_GPIOG_CLK_ENABLE();
  __HAL_RCC_GPIOD_CLK_ENABLE();

  /*Configure GPIO pin Output Level */
  HAL_GPIO_WritePin(GPIOE, OV7670_PWD_Pin|OV7670_RET_Pin, GPIO_PIN_RESET);

  /*Configure GPIO pin Output Level */
  HAL_GPIO_WritePin(GPIOC, LED_Status_Pin|LED_Error_Pin|GPIO_PIN_8, GPIO_PIN_RESET);

  /*Configure GPIO pin Output Level */
  HAL_GPIO_WritePin(GPIOG, ST7789_RST_Pin|ST7789_DC_Pin|ST7789_CS_Pin, GPIO_PIN_RESET);

  /*Configure GPIO pins : OV7670_PWD_Pin OV7670_RET_Pin */
  GPIO_InitStruct.Pin = OV7670_PWD_Pin|OV7670_RET_Pin;
  GPIO_InitStruct.Mode = GPIO_MODE_OUTPUT_PP;
  GPIO_InitStruct.Pull = GPIO_NOPULL;
  GPIO_InitStruct.Speed = GPIO_SPEED_FREQ_LOW;
  HAL_GPIO_Init(GPIOE, &GPIO_InitStruct);

  /*Configure GPIO pins : LED_Status_Pin LED_Error_Pin PC8 */
  GPIO_InitStruct.Pin = LED_Status_Pin|LED_Error_Pin|GPIO_PIN_8;
  GPIO_InitStruct.Mode = GPIO_MODE_OUTPUT_PP;
  GPIO_InitStruct.Pull = GPIO_NOPULL;
  GPIO_InitStruct.Speed = GPIO_SPEED_FREQ_LOW;
  HAL_GPIO_Init(GPIOC, &GPIO_InitStruct);

  /*Configure GPIO pin : PA1 */
  GPIO_InitStruct.Pin = GPIO_PIN_1;
  GPIO_InitStruct.Mode = GPIO_MODE_INPUT;
  GPIO_InitStruct.Pull = GPIO_NOPULL;
  HAL_GPIO_Init(GPIOA, &GPIO_InitStruct);

  /*Configure GPIO pin : ENC_IN_Pin */
  GPIO_InitStruct.Pin = ENC_IN_Pin;
  GPIO_InitStruct.Mode = GPIO_MODE_IT_FALLING;
  GPIO_InitStruct.Pull = GPIO_NOPULL;
  HAL_GPIO_Init(ENC_IN_GPIO_Port, &GPIO_InitStruct);

  /*Configure GPIO pin : ADDR0_Pin */
  GPIO_InitStruct.Pin = ADDR0_Pin;
  GPIO_InitStruct.Mode = GPIO_MODE_INPUT;
  GPIO_InitStruct.Pull = GPIO_NOPULL;
  HAL_GPIO_Init(ADDR0_GPIO_Port, &GPIO_InitStruct);

  /*Configure GPIO pins : ADDR1_Pin ADDR2_Pin ADDR3_Pin */
  GPIO_InitStruct.Pin = ADDR1_Pin|ADDR2_Pin|ADDR3_Pin;
  GPIO_InitStruct.Mode = GPIO_MODE_INPUT;
  GPIO_InitStruct.Pull = GPIO_NOPULL;
  HAL_GPIO_Init(GPIOD, &GPIO_InitStruct);

  /*Configure GPIO pin : PA8 */
  GPIO_InitStruct.Pin = GPIO_PIN_8;
  GPIO_InitStruct.Mode = GPIO_MODE_AF_PP;
  GPIO_InitStruct.Pull = GPIO_NOPULL;
  GPIO_InitStruct.Speed = GPIO_SPEED_FREQ_LOW;
  GPIO_InitStruct.Alternate = GPIO_AF0_MCO;
  HAL_GPIO_Init(GPIOA, &GPIO_InitStruct);

  /*Configure GPIO pins : ST7789_RST_Pin ST7789_DC_Pin ST7789_CS_Pin */
  GPIO_InitStruct.Pin = ST7789_RST_Pin|ST7789_DC_Pin|ST7789_CS_Pin;
  GPIO_InitStruct.Mode = GPIO_MODE_OUTPUT_PP;
  GPIO_InitStruct.Pull = GPIO_NOPULL;
  GPIO_InitStruct.Speed = GPIO_SPEED_FREQ_LOW;
  HAL_GPIO_Init(GPIOG, &GPIO_InitStruct);

  /* EXTI interrupt init*/
  HAL_NVIC_SetPriority(EXTI2_IRQn, 0, 0);
  HAL_NVIC_EnableIRQ(EXTI2_IRQn);

}

/* USER CODE BEGIN 4 */

/**
  * @brief  Perform the SDRAM exernal memory inialization sequence
  * @param  hsdram: SDRAM handle
  * @param  Command: Pointer to SDRAM command structure
  * @retval None
  */
static void SDRAM_Initialization_Sequence(SDRAM_HandleTypeDef *hsdram, FMC_SDRAM_CommandTypeDef *Command)
{
  __IO uint32_t tmpmrd =0;
  /* Step 3:  Configure a clock configuration enable command */
  Command->CommandMode 			 = FMC_SDRAM_CMD_CLK_ENABLE;
  Command->CommandTarget 		 = FMC_SDRAM_CMD_TARGET_BANK2;
  Command->AutoRefreshNumber 	 = 1;
  Command->ModeRegisterDefinition = 0;

  /* Send the command */
  HAL_SDRAM_SendCommand(hsdram, Command, 0x1000);

  /* Step 4: Insert 100 ms delay */
  HAL_Delay(100);

  /* Step 5: Configure a PALL (precharge all) command */
  Command->CommandMode 			 = FMC_SDRAM_CMD_PALL;
  Command->CommandTarget 	     = FMC_SDRAM_CMD_TARGET_BANK2;
  Command->AutoRefreshNumber 	 = 1;
  Command->ModeRegisterDefinition = 0;

  /* Send the command */
  HAL_SDRAM_SendCommand(hsdram, Command, 0x1000);

  /* Step 6 : Configure a Auto-Refresh command */
  Command->CommandMode 			 = FMC_SDRAM_CMD_AUTOREFRESH_MODE;
  Command->CommandTarget 		 = FMC_SDRAM_CMD_TARGET_BANK2;
  Command->AutoRefreshNumber 	 = 4;
  Command->ModeRegisterDefinition = 0;

  /* Send the command */
  HAL_SDRAM_SendCommand(hsdram, Command, 0x1000);

  /* Step 7: Program the external memory mode register */
  tmpmrd = (uint32_t)SDRAM_MODEREG_BURST_LENGTH_2          |
                     SDRAM_MODEREG_BURST_TYPE_SEQUENTIAL   |
                     SDRAM_MODEREG_CAS_LATENCY_3           |
                     SDRAM_MODEREG_OPERATING_MODE_STANDARD |
                     SDRAM_MODEREG_WRITEBURST_MODE_SINGLE;

  Command->CommandMode = FMC_SDRAM_CMD_LOAD_MODE;
  Command->CommandTarget 		 = FMC_SDRAM_CMD_TARGET_BANK2;
  Command->AutoRefreshNumber 	 = 1;
  Command->ModeRegisterDefinition = tmpmrd;

  /* Send the command */
  HAL_SDRAM_SendCommand(hsdram, Command, 0x1000);

  /* Step 8: Set the refresh rate counter */
  /* (15.62 us x Freq) - 20 */
  /* Set the device refresh counter */
  HAL_SDRAM_ProgramRefreshRate(hsdram, REFRESH_COUNT);
}

/**
  * @brief  Rx FIFO 0 callback.
  * @param  hfdcan: pointer to an FDCAN_HandleTypeDef structure that contains
  *         the configuration information for the specified FDCAN.
  * @param  RxFifo0ITs: indicates which Rx FIFO 0 interrupts are signalled.
  *                     This parameter can be any combination of @arg FDCAN_Rx_Fifo0_Interrupts.
  * @retval None
  */
void HAL_FDCAN_RxFifo0Callback(FDCAN_HandleTypeDef *hfdcan, uint32_t RxFifo0ITs)
{
  if((RxFifo0ITs & FDCAN_IT_RX_FIFO0_NEW_MESSAGE) != RESET)
  {
    /* Retreive Rx messages from RX FIFO0 */
    if (HAL_FDCAN_GetRxMessage(hfdcan, FDCAN_RX_FIFO0, &RxHeader, RxData) != HAL_OK)
    {
    /* Reception Error */
    Error_Handler();
    }

    /* Display LEDx */
    if ((RxHeader.Identifier == 0x321) && (RxHeader.IdType == FDCAN_STANDARD_ID) && (RxHeader.DataLength == FDCAN_DLC_BYTES_2))
    {

      //LED_Display(RxData[0]);
    	if( RxData[0] == 0x01){
    		led_val = RxData[1];
    		led_fill(led_val, led_val, led_val);
    		led_show();
    	}
    }

    if (HAL_FDCAN_ActivateNotification(hfdcan, FDCAN_IT_RX_FIFO0_NEW_MESSAGE, 0) != HAL_OK)
    {
      /* Notification Error */
      Error_Handler();
    }
  }
}

/* USER CODE END 4 */

void Error_Handler(void)
{
  __disable_irq();
  while (1)
  {
  }
}

/************************ (C) COPYRIGHT STMicroelectronics *****END OF FILE****/
